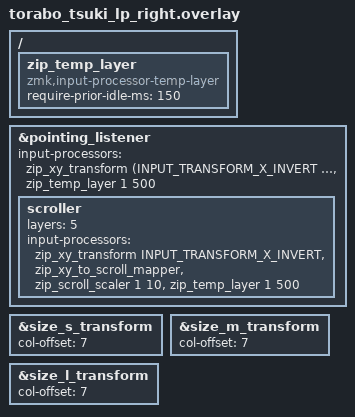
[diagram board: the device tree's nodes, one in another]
#include "torabo_tsuki_lp.dtsi"
#include <input/processors.dtsi>
#include <dt-bindings/zmk/input_transform.h>

/ {
    /omit-if-no-ref/ zip_temp_layer: zip_temp_layer {
        compatible = "zmk,input-processor-temp-layer";
        #input-processor-cells = <2>;
        require-prior-idle-ms = <150>;
    };
};

&pointing_listener {
    input-processors = 
        <&zip_xy_transform (INPUT_TRANSFORM_X_INVERT | INPUT_TRANSFORM_Y_INVERT)>,
        <&zip_temp_layer 1 500>;

    scroller {
        layers = <5>;
        input-processors =
            <&zip_xy_transform INPUT_TRANSFORM_X_INVERT>,
            <&zip_xy_to_scroll_mapper>,
            <&zip_scroll_scaler 1 10>,
            <&zip_temp_layer 1 500>;
    };
};

&size_s_transform {
    col-offset = <7>;
};

&size_m_transform {
    col-offset = <7>;
};

&size_l_transform {
    col-offset = <7>;
};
